# SAM9X60 device description
Architecture: ARM926EJS; Family: SAM9; Series: SAM9X
Registers are 32-bit, read-write, no defined reset value unless marked. A register's access mark holds for its fields unless they carry their own. Offsets are from the block's base; [hi:lo] are bit positions.

## RSTC — Reset Controller
Instances: RSTC 0xFFFFFE00
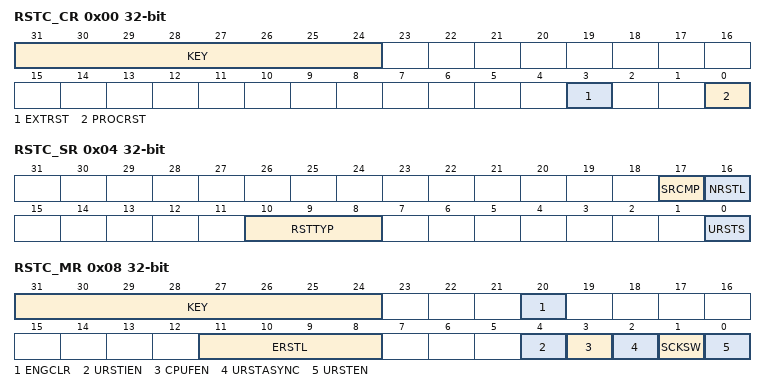
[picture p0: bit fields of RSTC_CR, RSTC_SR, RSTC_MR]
0x00 RSTC_CR wo — Control Register
  [31:24] KEY — System Reset Key
    165=PASSWD (Writing any other value in this field aborts the write operation.)
  [3] EXTRST — External Reset
  [0] PROCRST — Processor Reset
0x04 RSTC_SR ro — Status Register
  [17] SRCMP — Software Reset Command in Progress
  [16] NRSTL — NRST Pin Level
  [10:8] RSTTYP — Reset Type
    0=GENERAL_RST (First powerup reset); 1=BACKUP_RST (Return from Backup mode); 2=WDT_RST (Watchdog fault occurred); 3=SOFT_RST (Processor reset required by the software); 4=USER_RST (NRST pin detected low); 6=CPU_FAIL_RST (CPU clock failure detection occurred); 7=SLCK_XTAL_RST (32.768 kHz crystal failure detection fault occurred)
  [0] URSTS — User Reset Status
0x08 RSTC_MR — Mode Register
  [31:24] KEY — Write Access Password
    165=PASSWD (Writing any other value in this field aborts the write operation.Always reads as 0.)
  [20] ENGCLR — Enable GPBR Clear on Tamper Event
  [11:8] ERSTL — External Reset Length
  [4] URSTIEN — User Reset Interrupt Enable
  [3] CPUFEN — CPU Fail Enable
  [2] URSTASYNC — User Reset Asynchronous Control
  [1] SCKSW — Slow Clock Switching
  [0] URSTEN — User Reset Enable

## RTT — Real-time Timer
Instances: RTT 0xFFFFFE20
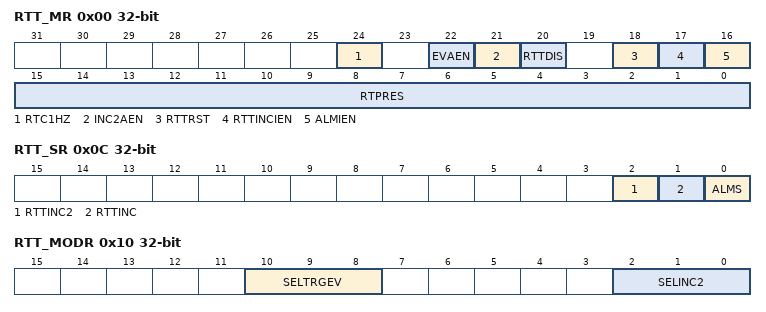
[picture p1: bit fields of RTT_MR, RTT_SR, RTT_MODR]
0x00 RTT_MR — Mode Register
  [24] RTC1HZ — Real-Time Clock 1Hz Clock Selection
  [22] EVAEN — Trigger Event Alarm Enable
  [21] INC2AEN — RTTINC2 Alarm Enable
  [20] RTTDIS — Real-time Timer Disable
  [18] RTTRST — Real-time Timer Restart
  [17] RTTINCIEN — Real-time Timer Increment Interrupt Enable
  [16] ALMIEN — Alarm Interrupt Enable
  [15:0] RTPRES — Real-time Timer Prescaler Value
0x04 RTT_AR — Alarm Register
  [31:0] ALMV — Alarm Value
0x08 RTT_VR ro — Value Register
  [31:0] CRTV — Current Real-time Value
0x0C RTT_SR ro — Status Register
  [2] RTTINC2 — Predefined Number of Prescaler Roll-overs Status (cleared on read)
  [1] RTTINC — Prescaler Roll-over Status (cleared on read)
  [0] ALMS — Real-time Alarm Status (cleared on read)
0x10 RTT_MODR — Modulo Selection Register
  [10:8] SELTRGEV — Selection of the 32-bit Counter Modulo to generate the trigger event
    0=NO_EVENT (No event generated); 1=MOD2 (Event occurs when CRTV modulo 2 equals 0); 2=MOD4 (Event occurs when CRTV modulo 4 equals 0); 3=MOD8 (Event occurs when CRTV modulo 8 equals 0); 4=MOD16 (Event occurs when CRTV modulo 16 equals 0); 5=MOD32 (Event occurs when CRTV modulo 32 equals 0); 6=MOD64 (Event occurs when CRTV modulo 64 equals 0); 7=MOD128 (Event occurs when CRTV modulo 128 equals 0)
  [2:0] SELINC2 — Selection of the 32-bit Counter Modulo to generate RTTINC2 flag
    0=NO_RTTINC2 (The RTTINC2 flag never rises); 1=MOD64 (The RTTINC2 flag is set when CRTV modulo 64 equals 0); 2=MOD128 (The RTTINC2 flag is set when CRTV modulo 128 equals 0); 3=MOD256 (The RTTINC2 flag is set when CRTV modulo 256 equals 0); 4=MOD512 (The RTTINC2 flag is set when CRTV modulo 512 equals 0); 5=MOD1024 (The RTTINC2 flag is set when CRTV modulo 1024 equals 0.Example: If RTPRES=32 then RTTINC2 flag rises once per second if the slow clock is 32.768 kHz.); 6=MOD2048 (The RTTINC2 flag is set when CRTV modulo 2048 equals 0); 7=MOD4096 (The RTTINC2 flag is set when CRTV modulo 4096 equals 0)
0x14 RTT_TSR ro — TimeStamp Register
  [23:0] TSTAMP — Real-time Timer Value Timestamp

## SCKC — Slow Clock Controller
Instances: SCKC 0xFFFFFE50
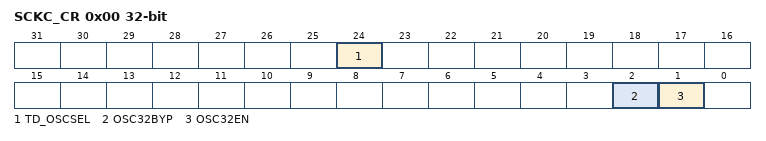
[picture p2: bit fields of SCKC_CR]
0x00 SCKC_CR — Slow Clock Controller Configuration Register
  [24] TD_OSCSEL — Timing Domain Slow Clock Selector
    0=RC (Slow clock of the timing domain is driven by the embedded 32 kHz (typical) RC oscillator.); 1=XTAL (Slow clock of the timing domain is driven by the 32.768 kHz crystal oscillator.)
  [2] OSC32BYP — 32.768 kHz Crystal Oscillator Bypass
  [1] OSC32EN — 32.768 kHz Crystal Oscillator
